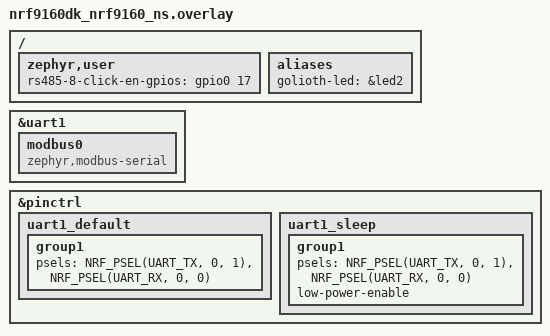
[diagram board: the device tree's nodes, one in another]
/*
 * Copyright (c) 2023-2024 Golioth, Inc.
 *
 * SPDX-License-Identifier: Apache-2.0
 */

/ {
	zephyr,user {
		rs485-8-click-en-gpios = <&gpio0 17 GPIO_ACTIVE_HIGH>;
	};

	aliases {
		golioth-led = &led2;
	};
};

&uart1 {
	status = "okay";

	modbus0 {
		compatible = "zephyr,modbus-serial";
		status = "okay";
	};
};

&pinctrl {
	/*
	 * The default pin group includes RTS/CTS HW flow control, but the Arduino
	 * Uno Click Shield board does not connect these pins (only TX/RX are used).
	 * This keeps RX/TX on the same pins, but just removes RTS/CTS from the
	 * pin groups.
	 */
	uart1_default: uart1_default {
		group1 {
			psels = <NRF_PSEL(UART_TX, 0, 1)>,
				<NRF_PSEL(UART_RX, 0, 0)>;
		};
	};

	uart1_sleep: uart1_sleep {
		group1 {
			psels = <NRF_PSEL(UART_TX, 0, 1)>,
				<NRF_PSEL(UART_RX, 0, 0)>;
			low-power-enable;
		};
	};
};
